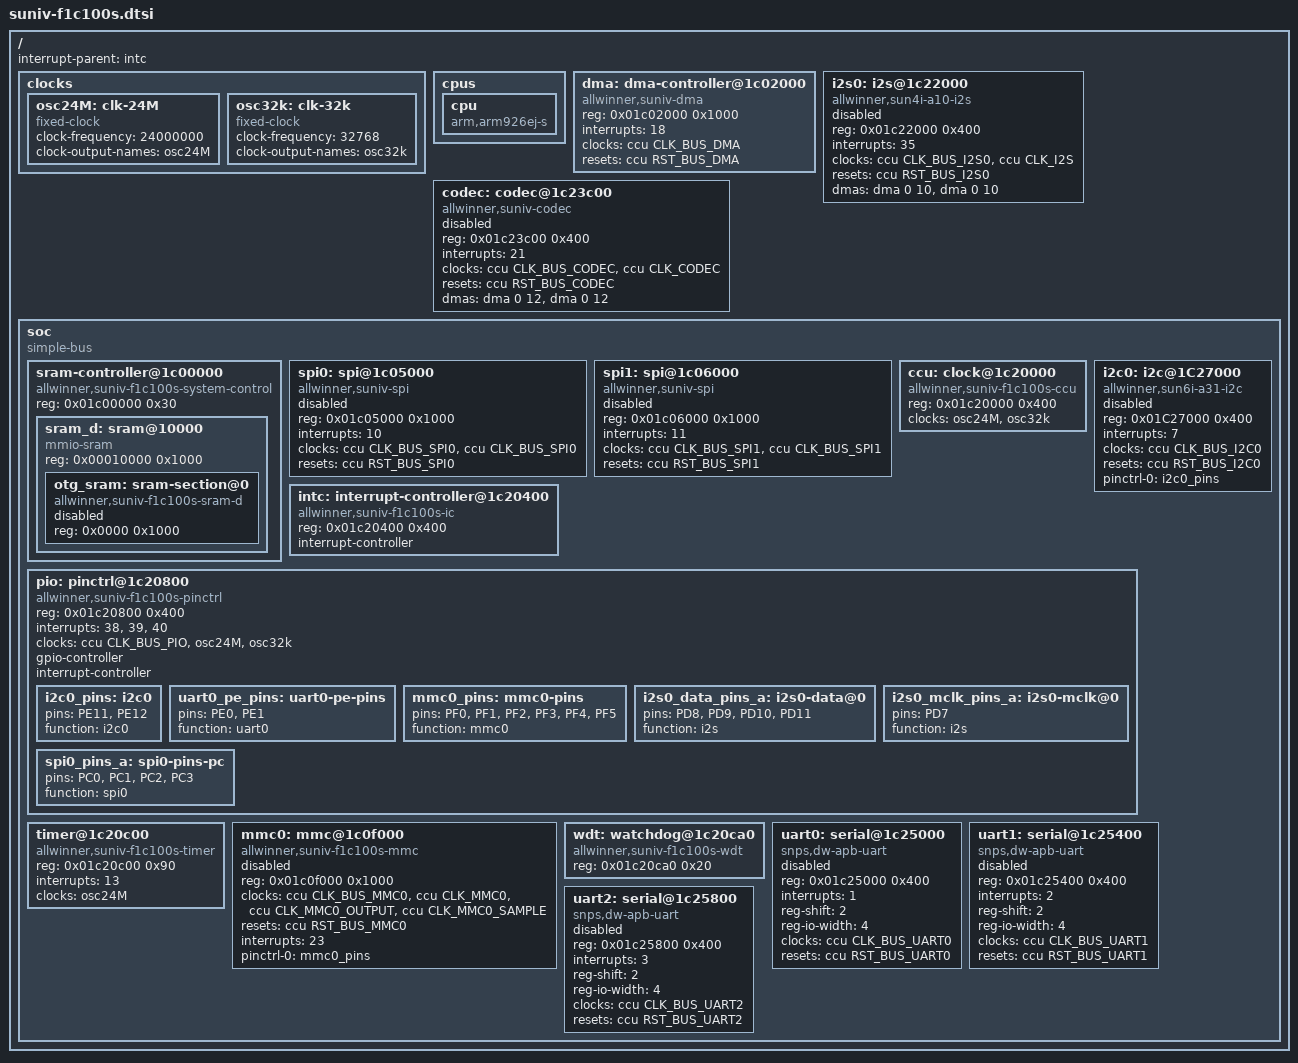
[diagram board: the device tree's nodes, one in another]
// SPDX-License-Identifier: (GPL-2.0+ OR X11)
/*
 * Copyright 2018 Icenowy Zheng <icenowy@aosc.io>
 * Copyright 2018 Mesih Kilinc <mesihkilinc@gmail.com>
 */

#include <dt-bindings/interrupt-controller/arm-gic.h>
#include <dt-bindings/clock/suniv-ccu-f1c100s.h>
#include <dt-bindings/reset/suniv-ccu-f1c100s.h>

/ {
	#address-cells = <1>;
	#size-cells = <1>;
	interrupt-parent = <&intc>;

	clocks {
		osc24M: clk-24M {
			#clock-cells = <0>;
			compatible = "fixed-clock";
			clock-frequency = <24000000>;
			clock-output-names = "osc24M";
		};

		osc32k: clk-32k {
			#clock-cells = <0>;
			compatible = "fixed-clock";
			clock-frequency = <32768>;
			clock-output-names = "osc32k";
		};
	};

	cpus {
		cpu {
			compatible = "arm,arm926ej-s";
			device_type = "cpu";
		};
	};

	dma: dma-controller@1c02000 {
		compatible = "allwinner,suniv-dma";
		reg = <0x01c02000 0x1000>;
		interrupts = <18>;
		clocks = <&ccu CLK_BUS_DMA>;
		resets = <&ccu RST_BUS_DMA>;
		#dma-cells = <2>;
	};


	i2s0: i2s@1c22000 {
		#sound-dai-cells = <0>;
		compatible = "allwinner,sun4i-a10-i2s";
		reg = <0x01c22000 0x400>;
		interrupts = <35>;
		clocks = <&ccu CLK_BUS_I2S0>, <&ccu CLK_I2S>;
		clock-names = "apb", "mod";
		resets = <&ccu RST_BUS_I2S0>;
		dmas = <&dma 0 10>,
		       <&dma 0 10>;
		dma-names = "rx", "tx";
		status = "disabled";
	};
	
	codec: codec@1c23c00 {
			compatible = "allwinner,suniv-codec";
			reg = <0x01c23c00 0x400>;
			interrupts = <21>;
			clocks = <&ccu CLK_BUS_CODEC>,
				 <&ccu CLK_CODEC>;
			clock-names = "apb", "codec";
			resets = <&ccu RST_BUS_CODEC>;
			dmas = <&dma 0 12>, <&dma 0 12>;
			dma-names = "rx", "tx";
			status = "disabled";
	};

	soc {
		compatible = "simple-bus";
		#address-cells = <1>;
		#size-cells = <1>;
		ranges;

		sram-controller@1c00000 {
			compatible = "allwinner,suniv-f1c100s-system-control",
				     "allwinner,sun4i-a10-system-control";
			reg = <0x01c00000 0x30>;
			#address-cells = <1>;
			#size-cells = <1>;
			ranges;

			sram_d: sram@10000 {
				compatible = "mmio-sram";
				reg = <0x00010000 0x1000>;
				#address-cells = <1>;
				#size-cells = <1>;
				ranges = <0 0x00010000 0x1000>;

				otg_sram: sram-section@0 {
					compatible = "allwinner,suniv-f1c100s-sram-d",
						     "allwinner,sun4i-a10-sram-d";
					reg = <0x0000 0x1000>;
					status = "disabled";
				};
			};
		};

		spi0: spi@1c05000 {
			compatible = "allwinner,suniv-spi",
				     "allwinner,sun8i-h3-spi";
			reg = <0x01c05000 0x1000>;
			interrupts = <10>;
			clocks = <&ccu CLK_BUS_SPI0>, <&ccu CLK_BUS_SPI0>;
			clock-names = "ahb", "mod";
			resets = <&ccu RST_BUS_SPI0>;
			status = "disabled";
			#address-cells = <1>;
			#size-cells = <0>;
		};

		spi1: spi@1c06000 {
			compatible = "allwinner,suniv-spi",
				     "allwinner,sun8i-h3-spi";
			reg = <0x01c06000 0x1000>;
			interrupts = <11>;
			clocks = <&ccu CLK_BUS_SPI1>, <&ccu CLK_BUS_SPI1>;
			clock-names = "ahb", "mod";
			resets = <&ccu RST_BUS_SPI1>;
			status = "disabled";
			#address-cells = <1>;
			#size-cells = <0>;
		};


		ccu: clock@1c20000 {
			compatible = "allwinner,suniv-f1c100s-ccu";
			reg = <0x01c20000 0x400>;
			clocks = <&osc24M>, <&osc32k>;
			clock-names = "hosc", "losc";
			#clock-cells = <1>;
			#reset-cells = <1>;
		};

		i2c0: i2c@1C27000 {
			compatible = "allwinner,sun6i-a31-i2c";
			reg = <0x01C27000 0x400>;
			interrupts = <7>;
			clocks = <&ccu CLK_BUS_I2C0>;
			resets = <&ccu RST_BUS_I2C0>;
			pinctrl-names = "default";
			pinctrl-0 = <&i2c0_pins>;
			status = "disabled";
			#address-cells = <1>;
			#size-cells = <0>;
		};

		intc: interrupt-controller@1c20400 {
			compatible = "allwinner,suniv-f1c100s-ic";
			reg = <0x01c20400 0x400>;
			interrupt-controller;
			#interrupt-cells = <1>;
		};

		pio: pinctrl@1c20800 {
			compatible = "allwinner,suniv-f1c100s-pinctrl";
			reg = <0x01c20800 0x400>;
			interrupts = <38>, <39>, <40>;
			clocks = <&ccu CLK_BUS_PIO>, <&osc24M>, <&osc32k>;
			clock-names = "apb", "hosc", "losc";
			gpio-controller;
			interrupt-controller;
			#interrupt-cells = <3>;
			#gpio-cells = <3>;

			i2c0_pins: i2c0 {
				pins = "PE11", "PE12";
				function = "i2c0";
                        };

			uart0_pe_pins: uart0-pe-pins {
				pins = "PE0", "PE1";
				function = "uart0";
			};
			
			
			mmc0_pins: mmc0-pins {
				pins = "PF0", "PF1", "PF2", "PF3", "PF4", "PF5";
				function = "mmc0";
			};
			
			i2s0_data_pins_a: i2s0-data@0 {
			        pins = "PD8", "PD9", "PD10", "PD11";
			        function = "i2s";
	        	};

		        i2s0_mclk_pins_a: i2s0-mclk@0 {
			        pins = "PD7";
			        function = "i2s";
		        };

			spi0_pins_a: spi0-pins-pc {
				pins = "PC0", "PC1", "PC2", "PC3";
				function = "spi0";
			};
		};

		timer@1c20c00 {
			compatible = "allwinner,suniv-f1c100s-timer";
			reg = <0x01c20c00 0x90>;
			interrupts = <13>;
			clocks = <&osc24M>;
		};

		mmc0: mmc@1c0f000 {
			compatible = "allwinner,suniv-f1c100s-mmc",
				     "allwinner,sun7i-a20-mmc";
			reg = <0x01c0f000 0x1000>;
			clocks = <&ccu CLK_BUS_MMC0>,
				 <&ccu CLK_MMC0>,
				 <&ccu CLK_MMC0_OUTPUT>,
				 <&ccu CLK_MMC0_SAMPLE>;
			clock-names = "ahb",
					      "mmc",
					      "output",
				    	  "sample";
			resets = <&ccu RST_BUS_MMC0>;
			reset-names = "ahb";
			interrupts = <23>;
			pinctrl-names = "default";
			pinctrl-0 = <&mmc0_pins>;
			status = "disabled";
			#address-cells = <1>;
			#size-cells = <0>;
		};

		wdt: watchdog@1c20ca0 {
			compatible = "allwinner,suniv-f1c100s-wdt",
				     "allwinner,sun4i-a10-wdt";
			reg = <0x01c20ca0 0x20>;
		};

		uart0: serial@1c25000 {
			compatible = "snps,dw-apb-uart";
			reg = <0x01c25000 0x400>;
			interrupts = <1>;
			reg-shift = <2>;
			reg-io-width = <4>;
			clocks = <&ccu CLK_BUS_UART0>;
			resets = <&ccu RST_BUS_UART0>;
			status = "disabled";
		};

		uart1: serial@1c25400 {
			compatible = "snps,dw-apb-uart";
			reg = <0x01c25400 0x400>;
			interrupts = <2>;
			reg-shift = <2>;
			reg-io-width = <4>;
			clocks = <&ccu CLK_BUS_UART1>;
			resets = <&ccu RST_BUS_UART1>;
			status = "disabled";
		};

		uart2: serial@1c25800 {
			compatible = "snps,dw-apb-uart";
			reg = <0x01c25800 0x400>;
			interrupts = <3>;
			reg-shift = <2>;
			reg-io-width = <4>;
			clocks = <&ccu CLK_BUS_UART2>;
			resets = <&ccu RST_BUS_UART2>;
			status = "disabled";
		};
	};
};
